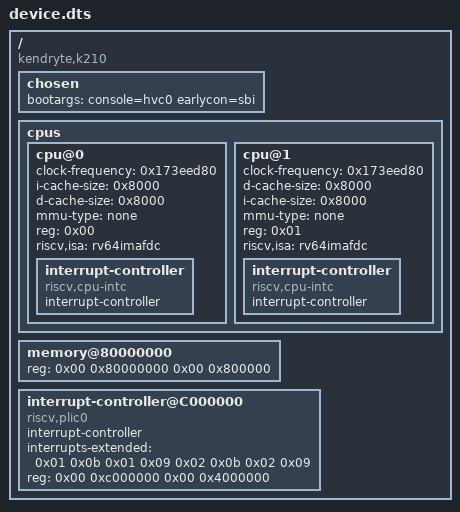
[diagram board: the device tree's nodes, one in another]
/dts-v1/;

/ {
	#address-cells = <0x02>;
	#size-cells = <0x02>;
	compatible = "kendryte,k210";

	chosen {
		bootargs = "console=hvc0 earlycon=sbi";
	};

	cpus {
		#address-cells = <0x01>;
		#size-cells = <0x00>;

		cpu@0 {
			device_type = "cpu";
			clock-frequency = <0x173eed80>;
			i-cache-size = <0x8000>;
			d-cache-size = <0x8000>;
			mmu-type = "none";
			reg = <0x00>;
			riscv,isa = "rv64imafdc";
			status = "okay";

			interrupt-controller {
				#interrupt-cells = <0x01>;
				compatible = "riscv,cpu-intc";
				interrupt-controller;
				phandle = <0x01>;
			};
		};

		cpu@1 {
			device_type = "cpu";
			clock-frequency = <0x173eed80>;
			d-cache-size = <0x8000>;
			i-cache-size = <0x8000>;
			mmu-type = "none";
			reg = <0x01>;
			riscv,isa = "rv64imafdc";
			status = "okay";

			interrupt-controller {
				#interrupt-cells = <0x01>;
				compatible = "riscv,cpu-intc";
				interrupt-controller;
				phandle = <0x02>;
			};
		};
	};

	memory@80000000 {
		device_type = "memory";
		reg = <0x00 0x80000000 0x00 0x800000>;
	};

	interrupt-controller@C000000 {
		#interrupt-cells = <0x01>;
		compatible = "riscv,plic0";
		interrupt-controller;
		interrupts-extended = <0x01 0x0b 0x01 0x09 0x02 0x0b 0x02 0x09>;
		reg = <0x00 0xc000000 0x00 0x4000000>;
	};
};
